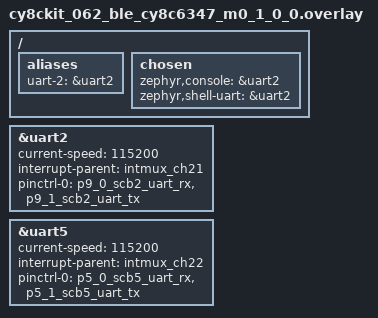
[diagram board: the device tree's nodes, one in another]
/*
 * Copyright (c) 2021, ATL Electronics
 *
 * SPDX-License-Identifier: Apache-2.0
 */

#include "cy8ckit_062_ble_cy8c6347-pinctrl.dtsi"

/ {
	aliases {
		uart-2 = &uart2;
	};

	chosen {
		zephyr,console = &uart2;
		zephyr,shell-uart = &uart2;
	};
};

&uart2 {
	status = "okay";
	current-speed = <115200>;

	interrupt-parent = <&intmux_ch21>;

	pinctrl-0 = <&p9_0_scb2_uart_rx &p9_1_scb2_uart_tx>;
	pinctrl-names = "default";

};

&uart5 {
	status = "okay";
	current-speed = <115200>;

	interrupt-parent = <&intmux_ch22>;

	pinctrl-0 = <&p5_0_scb5_uart_rx &p5_1_scb5_uart_tx>;
	pinctrl-names = "default";

};

arduino_serial: &uart5 {};
